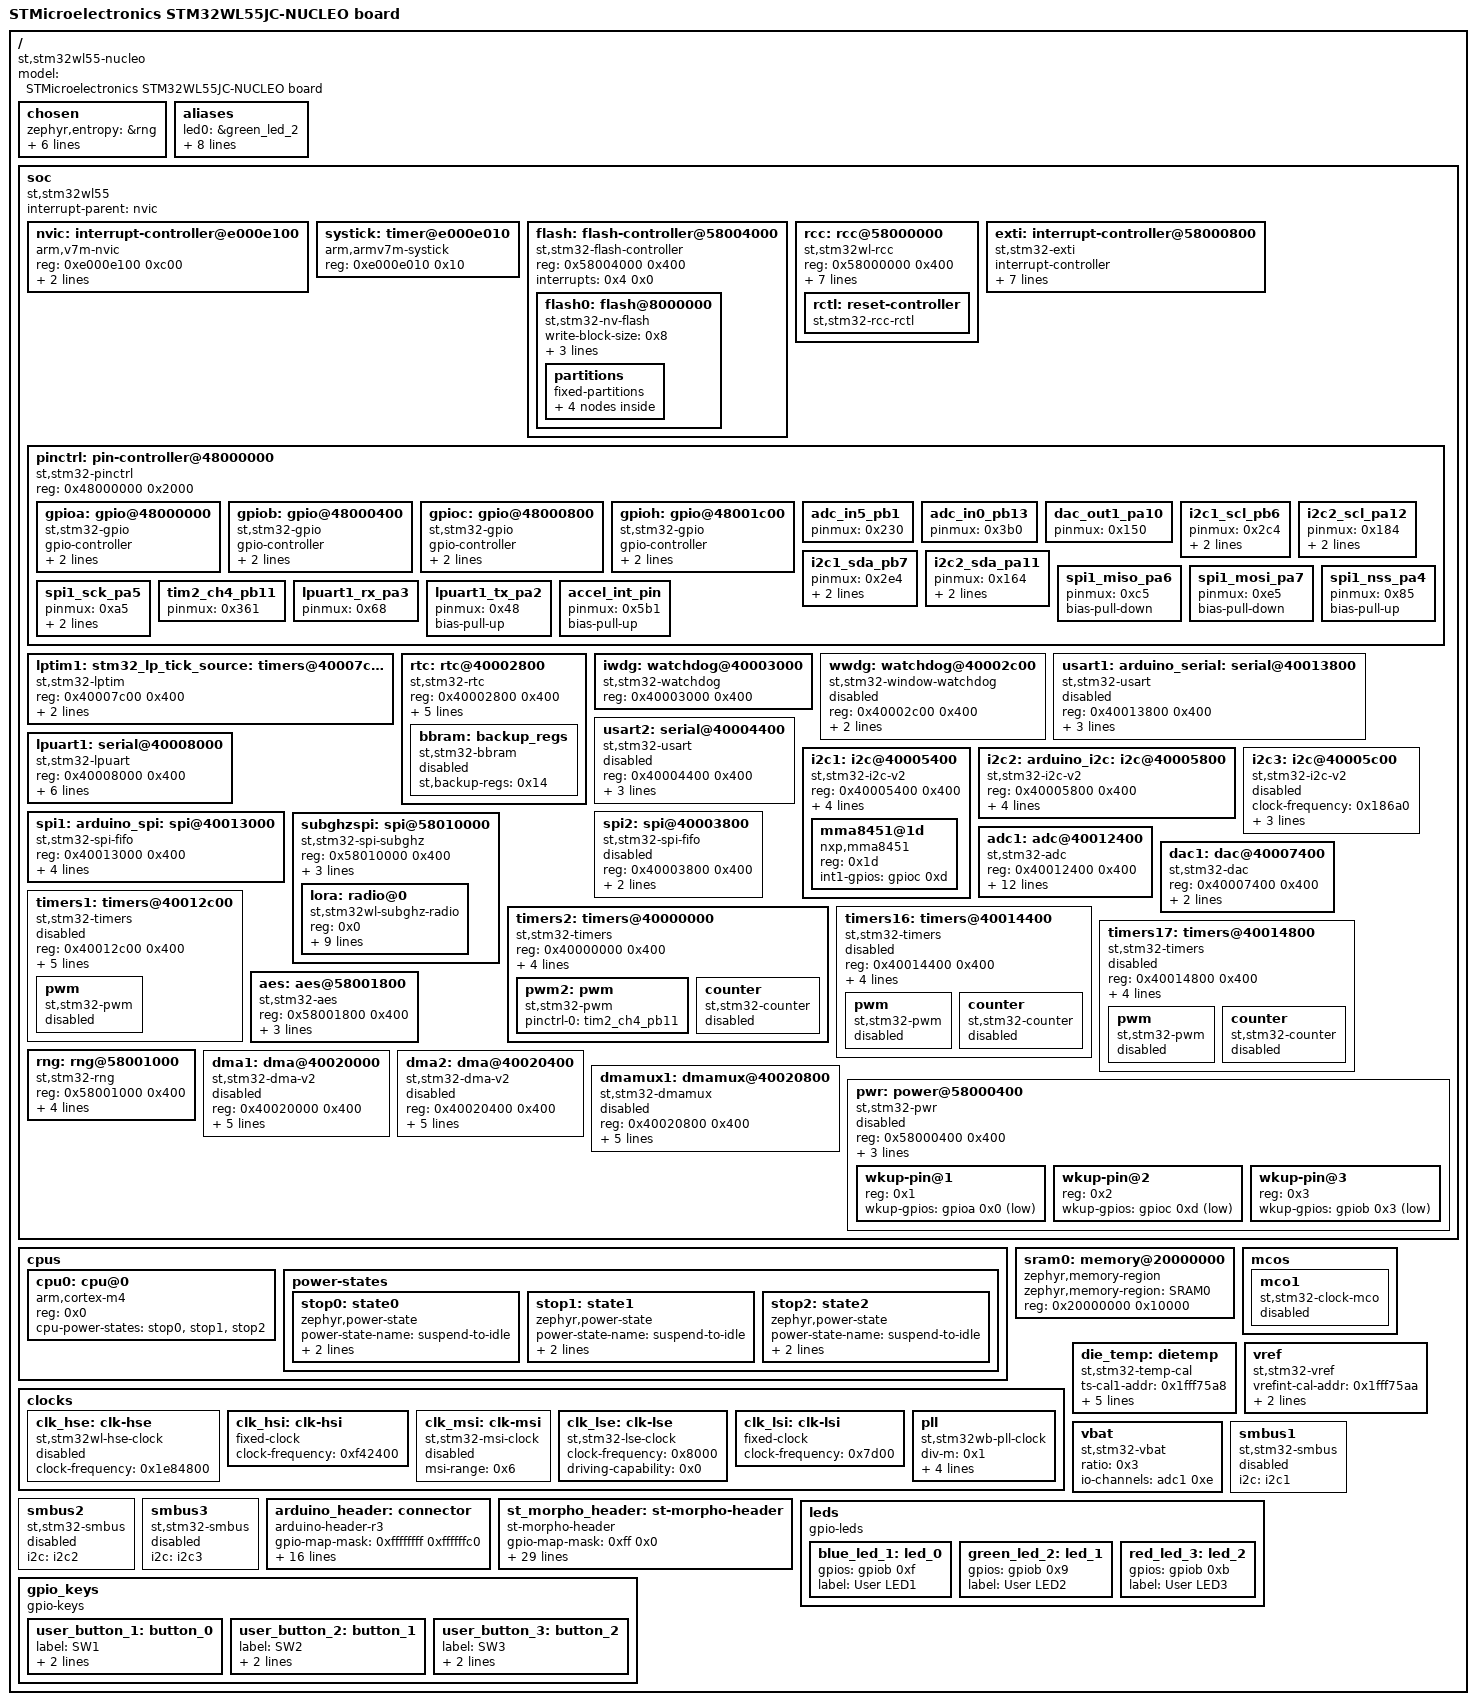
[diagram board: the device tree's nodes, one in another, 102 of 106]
/dts-v1/;

/* node '/' defined in zephyr\dts\common\skeleton.dtsi:9 */
/ {
	#address-cells = < 0x1 >;                              /* in zephyr\dts\common\skeleton.dtsi:10 */
	#size-cells = < 0x1 >;                                 /* in zephyr\dts\common\skeleton.dtsi:11 */
	model = "STMicroelectronics STM32WL55JC-NUCLEO board"; /* in zephyr\boards\st\nucleo_wl55jc\nucleo_wl55jc.dts:15 */
	compatible = "st,stm32wl55-nucleo";                    /* in zephyr\boards\st\nucleo_wl55jc\nucleo_wl55jc.dts:16 */

	/* node '/chosen' defined in zephyr\dts\common\skeleton.dtsi:13 */
	chosen {
		zephyr,entropy = &rng;                    /* in zephyr\dts\arm\st\wl\stm32wl.dtsi:23 */
		zephyr,flash-controller = &flash;         /* in zephyr\dts\arm\st\wl\stm32wl.dtsi:24 */
		zephyr,console = &lpuart1;                /* in zephyr\boards\st\nucleo_wl55jc\nucleo_wl55jc.dts:19 */
		zephyr,shell-uart = &lpuart1;             /* in zephyr\boards\st\nucleo_wl55jc\nucleo_wl55jc.dts:20 */
		zephyr,sram = &sram0;                     /* in zephyr\boards\st\nucleo_wl55jc\nucleo_wl55jc.dts:21 */
		zephyr,flash = &flash0;                   /* in zephyr\boards\st\nucleo_wl55jc\nucleo_wl55jc.dts:22 */
		zephyr,code-partition = &slot0_partition; /* in zephyr\boards\st\nucleo_wl55jc\nucleo_wl55jc.dts:23 */
	};

	/* node '/aliases' defined in zephyr\dts\common\skeleton.dtsi:15 */
	aliases {
		led0 = &green_led_2;   /* in zephyr\boards\st\nucleo_wl55jc\nucleo_wl55jc.dts:68 */
		sw0 = &user_button_1;  /* in zephyr\boards\st\nucleo_wl55jc\nucleo_wl55jc.dts:69 */
		sw1 = &user_button_2;  /* in zephyr\boards\st\nucleo_wl55jc\nucleo_wl55jc.dts:70 */
		sw2 = &user_button_3;  /* in zephyr\boards\st\nucleo_wl55jc\nucleo_wl55jc.dts:71 */
		lora0 = &lora;         /* in zephyr\boards\st\nucleo_wl55jc\nucleo_wl55jc.dts:72 */
		watchdog0 = &iwdg;     /* in zephyr\boards\st\nucleo_wl55jc\nucleo_wl55jc.dts:73 */
		die-temp0 = &die_temp; /* in zephyr\boards\st\nucleo_wl55jc\nucleo_wl55jc.dts:74 */
		volt-sensor0 = &vref;  /* in zephyr\boards\st\nucleo_wl55jc\nucleo_wl55jc.dts:75 */
		volt-sensor1 = &vbat;  /* in zephyr\boards\st\nucleo_wl55jc\nucleo_wl55jc.dts:76 */
	};

	/* node '/soc' defined in zephyr\dts\arm\armv7-m.dtsi:6 */
	soc {
		#address-cells = < 0x1 >;     /* in zephyr\dts\arm\armv7-m.dtsi:7 */
		#size-cells = < 0x1 >;        /* in zephyr\dts\arm\armv7-m.dtsi:8 */
		interrupt-parent = < &nvic >; /* in zephyr\dts\arm\armv7-m.dtsi:10 */
		ranges;                       /* in zephyr\dts\arm\armv7-m.dtsi:11 */
		compatible = "st,stm32wl55",
		             "st,stm32wl",
		             "simple-bus";    /* in zephyr\dts\arm\st\wl\stm32wl55.dtsi:11 */

		/* node '/soc/interrupt-controller@e000e100' defined in zephyr\dts\arm\armv7-m.dtsi:13 */
		nvic: interrupt-controller@e000e100 {
			#address-cells = < 0x1 >;            /* in zephyr\dts\arm\armv7-m.dtsi:14 */
			compatible = "arm,v7m-nvic";         /* in zephyr\dts\arm\armv7-m.dtsi:15 */
			reg = < 0xe000e100 0xc00 >;          /* in zephyr\dts\arm\armv7-m.dtsi:16 */
			interrupt-controller;                /* in zephyr\dts\arm\armv7-m.dtsi:17 */
			#interrupt-cells = < 0x2 >;          /* in zephyr\dts\arm\armv7-m.dtsi:18 */
			arm,num-irq-priority-bits = < 0x4 >; /* in zephyr\dts\arm\st\wl\stm32wl.dtsi:601 */
			phandle = < 0x1 >;                   /* in zephyr\dts\arm\armv7-m.dtsi:10 */
		};

		/* node '/soc/timer@e000e010' defined in zephyr\dts\arm\armv7-m.dtsi:21 */
		systick: timer@e000e010 {
			compatible = "arm,armv7m-systick"; /* in zephyr\dts\arm\armv7-m.dtsi:22 */
			reg = < 0xe000e010 0x10 >;         /* in zephyr\dts\arm\armv7-m.dtsi:23 */
		};

		/* node '/soc/flash-controller@58004000' defined in zephyr\dts\arm\st\wl\stm32wl.dtsi:120 */
		flash: flash-controller@58004000 {
			compatible = "st,stm32-flash-controller",
			             "st,stm32l4-flash-controller"; /* in zephyr\dts\arm\st\wl\stm32wl.dtsi:121 */
			reg = < 0x58004000 0x400 >;                 /* in zephyr\dts\arm\st\wl\stm32wl.dtsi:122 */
			interrupts = < 0x4 0x0 >;                   /* in zephyr\dts\arm\st\wl\stm32wl.dtsi:123 */
			#address-cells = < 0x1 >;                   /* in zephyr\dts\arm\st\wl\stm32wl.dtsi:125 */
			#size-cells = < 0x1 >;                      /* in zephyr\dts\arm\st\wl\stm32wl.dtsi:126 */

			/* node '/soc/flash-controller@58004000/flash@8000000' defined in zephyr\dts\arm\st\wl\stm32wl.dtsi:128 */
			flash0: flash@8000000 {
				compatible = "st,stm32-nv-flash",
				             "soc-nv-flash";      /* in zephyr\dts\arm\st\wl\stm32wl.dtsi:129 */
				write-block-size = < 0x8 >;       /* in zephyr\dts\arm\st\wl\stm32wl.dtsi:131 */
				erase-block-size = < 0x800 >;     /* in zephyr\dts\arm\st\wl\stm32wl.dtsi:132 */
				max-erase-time = < 0x19 >;        /* in zephyr\dts\arm\st\wl\stm32wl.dtsi:134 */
				reg = < 0x8000000 0x40000 >;      /* in zephyr\dts\arm\st\wl\stm32wl55Xc.dtsi:17 */

				/* node '/soc/flash-controller@58004000/flash@8000000/partitions' defined in zephyr\boards\st\nucleo_wl55jc\nucleo_wl55jc.dts:199 */
				partitions {
					compatible = "fixed-partitions"; /* in zephyr\boards\st\nucleo_wl55jc\nucleo_wl55jc.dts:200 */
					#address-cells = < 0x1 >;        /* in zephyr\boards\st\nucleo_wl55jc\nucleo_wl55jc.dts:201 */
					#size-cells = < 0x1 >;           /* in zephyr\boards\st\nucleo_wl55jc\nucleo_wl55jc.dts:202 */

					/* node '/soc/flash-controller@58004000/flash@8000000/partitions/partition@0' defined in zephyr\boards\st\nucleo_wl55jc\nucleo_wl55jc.dts:204 */
					boot_partition: partition@0 {
						label = "mcuboot";    /* in zephyr\boards\st\nucleo_wl55jc\nucleo_wl55jc.dts:205 */
						reg = < 0x0 0x8000 >; /* in zephyr\boards\st\nucleo_wl55jc\nucleo_wl55jc.dts:206 */
						read-only;            /* in zephyr\boards\st\nucleo_wl55jc\nucleo_wl55jc.dts:207 */
					};

					/* node '/soc/flash-controller@58004000/flash@8000000/partitions/partition@8000' defined in zephyr\boards\st\nucleo_wl55jc\nucleo_wl55jc.dts:210 */
					slot0_partition: partition@8000 {
						label = "image-0";        /* in zephyr\boards\st\nucleo_wl55jc\nucleo_wl55jc.dts:211 */
						reg = < 0x8000 0x1a000 >; /* in zephyr\boards\st\nucleo_wl55jc\nucleo_wl55jc.dts:212 */
					};

					/* node '/soc/flash-controller@58004000/flash@8000000/partitions/partition@22000' defined in zephyr\boards\st\nucleo_wl55jc\nucleo_wl55jc.dts:215 */
					slot1_partition: partition@22000 {
						label = "image-1";         /* in zephyr\boards\st\nucleo_wl55jc\nucleo_wl55jc.dts:216 */
						reg = < 0x22000 0x1a000 >; /* in zephyr\boards\st\nucleo_wl55jc\nucleo_wl55jc.dts:217 */
					};

					/* node '/soc/flash-controller@58004000/flash@8000000/partitions/partition@3c000' defined in zephyr\boards\st\nucleo_wl55jc\nucleo_wl55jc.dts:224 */
					storage_partition: partition@3c000 {
						label = "storage";        /* in zephyr\boards\st\nucleo_wl55jc\nucleo_wl55jc.dts:225 */
						reg = < 0x3c000 0x4000 >; /* in zephyr\boards\st\nucleo_wl55jc\nucleo_wl55jc.dts:226 */
					};
				};
			};
		};

		/* node '/soc/rcc@58000000' defined in zephyr\dts\arm\st\wl\stm32wl.dtsi:138 */
		rcc: rcc@58000000 {
			compatible = "st,stm32wl-rcc";   /* in zephyr\dts\arm\st\wl\stm32wl.dtsi:139 */
			#clock-cells = < 0x2 >;          /* in zephyr\dts\arm\st\wl\stm32wl.dtsi:140 */
			reg = < 0x58000000 0x400 >;      /* in zephyr\dts\arm\st\wl\stm32wl.dtsi:141 */
			clocks = < &pll >;               /* in zephyr\boards\st\nucleo_wl55jc\nucleo_wl55jc.dts:108 */
			clock-frequency = < 0x2dc6c00 >; /* in zephyr\boards\st\nucleo_wl55jc\nucleo_wl55jc.dts:109 */
			cpu1-prescaler = < 0x1 >;        /* in zephyr\boards\st\nucleo_wl55jc\nucleo_wl55jc.dts:110 */
			cpu2-prescaler = < 0x1 >;        /* in zephyr\boards\st\nucleo_wl55jc\nucleo_wl55jc.dts:111 */
			ahb3-prescaler = < 0x1 >;        /* in zephyr\boards\st\nucleo_wl55jc\nucleo_wl55jc.dts:112 */
			apb1-prescaler = < 0x1 >;        /* in zephyr\boards\st\nucleo_wl55jc\nucleo_wl55jc.dts:113 */
			apb2-prescaler = < 0x1 >;        /* in zephyr\boards\st\nucleo_wl55jc\nucleo_wl55jc.dts:114 */
			phandle = < 0x3 >;               /* in zephyr\dts\arm\st\wl\stm32wl.dtsi:155 */

			/* node '/soc/rcc@58000000/reset-controller' defined in zephyr\dts\arm\st\wl\stm32wl.dtsi:143 */
			rctl: reset-controller {
				compatible = "st,stm32-rcc-rctl"; /* in zephyr\dts\arm\st\wl\stm32wl.dtsi:144 */
				#reset-cells = < 0x1 >;           /* in zephyr\dts\arm\st\wl\stm32wl.dtsi:145 */
				phandle = < 0x4 >;                /* in zephyr\dts\arm\st\wl\stm32wl.dtsi:256 */
			};
		};

		/* node '/soc/interrupt-controller@58000800' defined in zephyr\dts\arm\st\wl\stm32wl.dtsi:149 */
		exti: interrupt-controller@58000800 {
			compatible = "st,stm32-exti";  /* in zephyr\dts\arm\st\wl\stm32wl.dtsi:150 */
			interrupt-controller;          /* in zephyr\dts\arm\st\wl\stm32wl.dtsi:151 */
			#interrupt-cells = < 0x1 >;    /* in zephyr\dts\arm\st\wl\stm32wl.dtsi:152 */
			#address-cells = < 0x1 >;      /* in zephyr\dts\arm\st\wl\stm32wl.dtsi:153 */
			reg = < 0x58000800 0x400 >;    /* in zephyr\dts\arm\st\wl\stm32wl.dtsi:154 */
			clocks = < &rcc 0x54 0x100 >;  /* in zephyr\dts\arm\st\wl\stm32wl.dtsi:155 */
			num-lines = < 0x40 >;          /* in zephyr\dts\arm\st\wl\stm32wl.dtsi:156 */
			interrupts = < 0x6 0x0 >,
			             < 0x7 0x0 >,
			             < 0x8 0x0 >,
			             < 0x9 0x0 >,
			             < 0xa 0x0 >,
			             < 0x16 0x0 >,
			             < 0x29 0x0 >;     /* in zephyr\dts\arm\st\wl\stm32wl.dtsi:157 */
			interrupt-names = "line0",
			                  "line1",
			                  "line2",
			                  "line3",
			                  "line4",
			                  "line5-9",
			                  "line10-15"; /* in zephyr\dts\arm\st\wl\stm32wl.dtsi:159 */
			line-ranges = < 0x0 0x1 >,
			              < 0x1 0x1 >,
			              < 0x2 0x1 >,
			              < 0x3 0x1 >,
			              < 0x4 0x1 >,
			              < 0x5 0x5 >,
			              < 0xa 0x6 >;     /* in zephyr\dts\arm\st\wl\stm32wl.dtsi:161 */
		};

		/* node '/soc/pin-controller@48000000' defined in zephyr\dts\arm\st\wl\stm32wl.dtsi:165 */
		pinctrl: pin-controller@48000000 {
			compatible = "st,stm32-pinctrl"; /* in zephyr\dts\arm\st\wl\stm32wl.dtsi:166 */
			#address-cells = < 0x1 >;        /* in zephyr\dts\arm\st\wl\stm32wl.dtsi:167 */
			#size-cells = < 0x1 >;           /* in zephyr\dts\arm\st\wl\stm32wl.dtsi:168 */
			reg = < 0x48000000 0x2000 >;     /* in zephyr\dts\arm\st\wl\stm32wl.dtsi:169 */

			/* node '/soc/pin-controller@48000000/gpio@48000000' defined in zephyr\dts\arm\st\wl\stm32wl.dtsi:171 */
			gpioa: gpio@48000000 {
				compatible = "st,stm32-gpio"; /* in zephyr\dts\arm\st\wl\stm32wl.dtsi:172 */
				gpio-controller;              /* in zephyr\dts\arm\st\wl\stm32wl.dtsi:173 */
				#gpio-cells = < 0x2 >;        /* in zephyr\dts\arm\st\wl\stm32wl.dtsi:174 */
				reg = < 0x48000000 0x400 >;   /* in zephyr\dts\arm\st\wl\stm32wl.dtsi:175 */
				clocks = < &rcc 0x4c 0x1 >;   /* in zephyr\dts\arm\st\wl\stm32wl.dtsi:176 */
				phandle = < 0x14 >;           /* in zephyr\dts\arm\st\wl\stm32wl.dtsi:534 */
			};

			/* node '/soc/pin-controller@48000000/gpio@48000400' defined in zephyr\dts\arm\st\wl\stm32wl.dtsi:179 */
			gpiob: gpio@48000400 {
				compatible = "st,stm32-gpio"; /* in zephyr\dts\arm\st\wl\stm32wl.dtsi:180 */
				gpio-controller;              /* in zephyr\dts\arm\st\wl\stm32wl.dtsi:181 */
				#gpio-cells = < 0x2 >;        /* in zephyr\dts\arm\st\wl\stm32wl.dtsi:182 */
				reg = < 0x48000400 0x400 >;   /* in zephyr\dts\arm\st\wl\stm32wl.dtsi:183 */
				clocks = < &rcc 0x4c 0x2 >;   /* in zephyr\dts\arm\st\wl\stm32wl.dtsi:184 */
				phandle = < 0x15 >;           /* in zephyr\dts\arm\st\wl\stm32wl.dtsi:544 */
			};

			/* node '/soc/pin-controller@48000000/gpio@48000800' defined in zephyr\dts\arm\st\wl\stm32wl.dtsi:187 */
			gpioc: gpio@48000800 {
				compatible = "st,stm32-gpio"; /* in zephyr\dts\arm\st\wl\stm32wl.dtsi:188 */
				gpio-controller;              /* in zephyr\dts\arm\st\wl\stm32wl.dtsi:189 */
				#gpio-cells = < 0x2 >;        /* in zephyr\dts\arm\st\wl\stm32wl.dtsi:190 */
				reg = < 0x48000800 0x400 >;   /* in zephyr\dts\arm\st\wl\stm32wl.dtsi:191 */
				clocks = < &rcc 0x4c 0x4 >;   /* in zephyr\dts\arm\st\wl\stm32wl.dtsi:192 */
				phandle = < 0x9 >;            /* in ..\Desktop\Universidad\Master\Embedded\prototipo_acelerometro\build\zephyr\boards\nucleo_wl55jc.overlay:15 */
			};

			/* node '/soc/pin-controller@48000000/gpio@48001c00' defined in zephyr\dts\arm\st\wl\stm32wl.dtsi:195 */
			gpioh: gpio@48001c00 {
				compatible = "st,stm32-gpio"; /* in zephyr\dts\arm\st\wl\stm32wl.dtsi:196 */
				gpio-controller;              /* in zephyr\dts\arm\st\wl\stm32wl.dtsi:197 */
				#gpio-cells = < 0x2 >;        /* in zephyr\dts\arm\st\wl\stm32wl.dtsi:198 */
				reg = < 0x48001c00 0x400 >;   /* in zephyr\dts\arm\st\wl\stm32wl.dtsi:199 */
				clocks = < &rcc 0x4c 0x80 >;  /* in zephyr\dts\arm\st\wl\stm32wl.dtsi:200 */
				phandle = < 0x1e >;           /* in zephyr\boards\st\nucleo_wl55jc\st_morpho_connector.dtsi:15 */
			};

			/* node '/soc/pin-controller@48000000/adc_in5_pb1' defined in modules\hal\stm32\dts\st\wl\stm32wl55jcix-pinctrl.dtsi:39 */
			adc_in5_pb1: adc_in5_pb1 {
				pinmux = < 0x230 >; /* in modules\hal\stm32\dts\st\wl\stm32wl55jcix-pinctrl.dtsi:40 */
				phandle = < 0x10 >; /* in zephyr\boards\st\nucleo_wl55jc\nucleo_wl55jc.dts:155 */
			};

			/* node '/soc/pin-controller@48000000/adc_in0_pb13' defined in modules\hal\stm32\dts\st\wl\stm32wl55jcix-pinctrl.dtsi:55 */
			adc_in0_pb13: adc_in0_pb13 {
				pinmux = < 0x3b0 >; /* in modules\hal\stm32\dts\st\wl\stm32wl55jcix-pinctrl.dtsi:56 */
				phandle = < 0x11 >; /* in zephyr\boards\st\nucleo_wl55jc\nucleo_wl55jc.dts:155 */
			};

			/* node '/soc/pin-controller@48000000/dac_out1_pa10' defined in modules\hal\stm32\dts\st\wl\stm32wl55jcix-pinctrl.dtsi:323 */
			dac_out1_pa10: dac_out1_pa10 {
				pinmux = < 0x150 >; /* in modules\hal\stm32\dts\st\wl\stm32wl55jcix-pinctrl.dtsi:324 */
				phandle = < 0x12 >; /* in zephyr\boards\st\nucleo_wl55jc\nucleo_wl55jc.dts:139 */
			};

			/* node '/soc/pin-controller@48000000/i2c1_scl_pb6' defined in modules\hal\stm32\dts\st\wl\stm32wl55jcix-pinctrl.dtsi:335 */
			i2c1_scl_pb6: i2c1_scl_pb6 {
				pinmux = < 0x2c4 >; /* in modules\hal\stm32\dts\st\wl\stm32wl55jcix-pinctrl.dtsi:336 */
				bias-pull-up;       /* in modules\hal\stm32\dts\st\wl\stm32wl55jcix-pinctrl.dtsi:337 */
				drive-open-drain;   /* in modules\hal\stm32\dts\st\wl\stm32wl55jcix-pinctrl.dtsi:338 */
				phandle = < 0x7 >;  /* in ..\Desktop\Universidad\Master\Embedded\prototipo_acelerometro\build\zephyr\boards\nucleo_wl55jc.overlay:6 */
			};

			/* node '/soc/pin-controller@48000000/i2c2_scl_pa12' defined in modules\hal\stm32\dts\st\wl\stm32wl55jcix-pinctrl.dtsi:347 */
			i2c2_scl_pa12: i2c2_scl_pa12 {
				pinmux = < 0x184 >; /* in modules\hal\stm32\dts\st\wl\stm32wl55jcix-pinctrl.dtsi:348 */
				bias-pull-up;       /* in modules\hal\stm32\dts\st\wl\stm32wl55jcix-pinctrl.dtsi:349 */
				drive-open-drain;   /* in modules\hal\stm32\dts\st\wl\stm32wl55jcix-pinctrl.dtsi:350 */
				phandle = < 0xa >;  /* in zephyr\boards\st\nucleo_wl55jc\nucleo_wl55jc.dts:125 */
			};

			/* node '/soc/pin-controller@48000000/i2c1_sda_pb7' defined in modules\hal\stm32\dts\st\wl\stm32wl55jcix-pinctrl.dtsi:391 */
			i2c1_sda_pb7: i2c1_sda_pb7 {
				pinmux = < 0x2e4 >; /* in modules\hal\stm32\dts\st\wl\stm32wl55jcix-pinctrl.dtsi:392 */
				bias-pull-up;       /* in modules\hal\stm32\dts\st\wl\stm32wl55jcix-pinctrl.dtsi:393 */
				drive-open-drain;   /* in modules\hal\stm32\dts\st\wl\stm32wl55jcix-pinctrl.dtsi:394 */
				phandle = < 0x8 >;  /* in ..\Desktop\Universidad\Master\Embedded\prototipo_acelerometro\build\zephyr\boards\nucleo_wl55jc.overlay:6 */
			};

			/* node '/soc/pin-controller@48000000/i2c2_sda_pa11' defined in modules\hal\stm32\dts\st\wl\stm32wl55jcix-pinctrl.dtsi:403 */
			i2c2_sda_pa11: i2c2_sda_pa11 {
				pinmux = < 0x164 >; /* in modules\hal\stm32\dts\st\wl\stm32wl55jcix-pinctrl.dtsi:404 */
				bias-pull-up;       /* in modules\hal\stm32\dts\st\wl\stm32wl55jcix-pinctrl.dtsi:405 */
				drive-open-drain;   /* in modules\hal\stm32\dts\st\wl\stm32wl55jcix-pinctrl.dtsi:406 */
				phandle = < 0xb >;  /* in zephyr\boards\st\nucleo_wl55jc\nucleo_wl55jc.dts:125 */
			};

			/* node '/soc/pin-controller@48000000/spi1_miso_pa6' defined in modules\hal\stm32\dts\st\wl\stm32wl55jcix-pinctrl.dtsi:583 */
			spi1_miso_pa6: spi1_miso_pa6 {
				pinmux = < 0xc5 >; /* in modules\hal\stm32\dts\st\wl\stm32wl55jcix-pinctrl.dtsi:584 */
				bias-pull-down;    /* in modules\hal\stm32\dts\st\wl\stm32wl55jcix-pinctrl.dtsi:585 */
				phandle = < 0xe >; /* in zephyr\boards\st\nucleo_wl55jc\nucleo_wl55jc.dts:132 */
			};

			/* node '/soc/pin-controller@48000000/spi1_mosi_pa7' defined in modules\hal\stm32\dts\st\wl\stm32wl55jcix-pinctrl.dtsi:615 */
			spi1_mosi_pa7: spi1_mosi_pa7 {
				pinmux = < 0xe5 >; /* in modules\hal\stm32\dts\st\wl\stm32wl55jcix-pinctrl.dtsi:616 */
				bias-pull-down;    /* in modules\hal\stm32\dts\st\wl\stm32wl55jcix-pinctrl.dtsi:617 */
				phandle = < 0xf >; /* in zephyr\boards\st\nucleo_wl55jc\nucleo_wl55jc.dts:132 */
			};

			/* node '/soc/pin-controller@48000000/spi1_nss_pa4' defined in modules\hal\stm32\dts\st\wl\stm32wl55jcix-pinctrl.dtsi:652 */
			spi1_nss_pa4: spi1_nss_pa4 {
				pinmux = < 0x85 >; /* in modules\hal\stm32\dts\st\wl\stm32wl55jcix-pinctrl.dtsi:653 */
				bias-pull-up;      /* in modules\hal\stm32\dts\st\wl\stm32wl55jcix-pinctrl.dtsi:654 */
				phandle = < 0xc >; /* in zephyr\boards\st\nucleo_wl55jc\nucleo_wl55jc.dts:132 */
			};

			/* node '/soc/pin-controller@48000000/spi1_sck_pa5' defined in modules\hal\stm32\dts\st\wl\stm32wl55jcix-pinctrl.dtsi:690 */
			spi1_sck_pa5: spi1_sck_pa5 {
				pinmux = < 0xa5 >;             /* in modules\hal\stm32\dts\st\wl\stm32wl55jcix-pinctrl.dtsi:691 */
				bias-pull-down;                /* in modules\hal\stm32\dts\st\wl\stm32wl55jcix-pinctrl.dtsi:692 */
				slew-rate = "very-high-speed"; /* in modules\hal\stm32\dts\st\wl\stm32wl55jcix-pinctrl.dtsi:693 */
				phandle = < 0xd >;             /* in zephyr\boards\st\nucleo_wl55jc\nucleo_wl55jc.dts:132 */
			};

			/* node '/soc/pin-controller@48000000/tim2_ch4_pb11' defined in modules\hal\stm32\dts\st\wl\stm32wl55jcix-pinctrl.dtsi:830 */
			tim2_ch4_pb11: tim2_ch4_pb11 {
				pinmux = < 0x361 >; /* in modules\hal\stm32\dts\st\wl\stm32wl55jcix-pinctrl.dtsi:831 */
				phandle = < 0x13 >; /* in zephyr\boards\st\nucleo_wl55jc\nucleo_wl55jc.dts:149 */
			};

			/* node '/soc/pin-controller@48000000/lpuart1_rx_pa3' defined in modules\hal\stm32\dts\st\wl\stm32wl55jcix-pinctrl.dtsi:941 */
			lpuart1_rx_pa3: lpuart1_rx_pa3 {
				pinmux = < 0x68 >; /* in modules\hal\stm32\dts\st\wl\stm32wl55jcix-pinctrl.dtsi:942 */
				phandle = < 0x6 >; /* in zephyr\boards\st\nucleo_wl55jc\nucleo_wl55jc.dts:118 */
			};

			/* node '/soc/pin-controller@48000000/lpuart1_tx_pa2' defined in modules\hal\stm32\dts\st\wl\stm32wl55jcix-pinctrl.dtsi:967 */
			lpuart1_tx_pa2: lpuart1_tx_pa2 {
				pinmux = < 0x48 >; /* in modules\hal\stm32\dts\st\wl\stm32wl55jcix-pinctrl.dtsi:968 */
				bias-pull-up;      /* in modules\hal\stm32\dts\st\wl\stm32wl55jcix-pinctrl.dtsi:969 */
				phandle = < 0x5 >; /* in zephyr\boards\st\nucleo_wl55jc\nucleo_wl55jc.dts:118 */
			};

			/* node '/soc/pin-controller@48000000/accel_int_pin' defined in ..\Desktop\Universidad\Master\Embedded\prototipo_acelerometro\build\zephyr\boards\nucleo_wl55jc.overlay:22 */
			accel_int_pin: accel_int_pin {
				pinmux = < 0x5b1 >; /* in ..\Desktop\Universidad\Master\Embedded\prototipo_acelerometro\build\zephyr\boards\nucleo_wl55jc.overlay:23 */
				bias-pull-up;       /* in ..\Desktop\Universidad\Master\Embedded\prototipo_acelerometro\build\zephyr\boards\nucleo_wl55jc.overlay:24 */
			};
		};

		/* node '/soc/timers@40007c00' defined in zephyr\dts\arm\st\wl\stm32wl.dtsi:204 */
		lptim1: stm32_lp_tick_source: timers@40007c00 {
			compatible = "st,stm32-lptim";     /* in zephyr\dts\arm\st\wl\stm32wl.dtsi:205 */
			#address-cells = < 0x1 >;          /* in zephyr\dts\arm\st\wl\stm32wl.dtsi:207 */
			#size-cells = < 0x0 >;             /* in zephyr\dts\arm\st\wl\stm32wl.dtsi:208 */
			reg = < 0x40007c00 0x400 >;        /* in zephyr\dts\arm\st\wl\stm32wl.dtsi:209 */
			interrupts = < 0x27 0x1 >;         /* in zephyr\dts\arm\st\wl\stm32wl.dtsi:210 */
			interrupt-names = "wakeup";        /* in zephyr\dts\arm\st\wl\stm32wl.dtsi:211 */
			clocks = < &rcc 0x58 0x80000000 >,
			         < &rcc 0x3 0x8d20088 >;   /* in zephyr\boards\st\nucleo_wl55jc\nucleo_wl55jc.dts:85 */
			status = "okay";                   /* in zephyr\boards\st\nucleo_wl55jc\nucleo_wl55jc.dts:87 */
		};

		/* node '/soc/rtc@40002800' defined in zephyr\dts\arm\st\wl\stm32wl.dtsi:215 */
		rtc: rtc@40002800 {
			compatible = "st,stm32-rtc";     /* in zephyr\dts\arm\st\wl\stm32wl.dtsi:216 */
			reg = < 0x40002800 0x400 >;      /* in zephyr\dts\arm\st\wl\stm32wl.dtsi:217 */
			interrupts = < 0x2a 0x0 >;       /* in zephyr\dts\arm\st\wl\stm32wl.dtsi:218 */
			prescaler = < 0x8000 >;          /* in zephyr\dts\arm\st\wl\stm32wl.dtsi:220 */
			alarms-count = < 0x2 >;          /* in zephyr\dts\arm\st\wl\stm32wl.dtsi:221 */
			alrm-exti-line = < 0x11 >;       /* in zephyr\dts\arm\st\wl\stm32wl.dtsi:222 */
			clocks = < &rcc 0x58 0x400 >,
			         < &rcc 0x2 0x8c80090 >; /* in zephyr\boards\st\nucleo_wl55jc\nucleo_wl55jc.dts:232 */
			status = "okay";                 /* in zephyr\boards\st\nucleo_wl55jc\nucleo_wl55jc.dts:234 */

			/* node '/soc/rtc@40002800/backup_regs' defined in zephyr\dts\arm\st\wl\stm32wl.dtsi:231 */
			bbram: backup_regs {
				compatible = "st,stm32-bbram"; /* in zephyr\dts\arm\st\wl\stm32wl.dtsi:232 */
				st,backup-regs = < 0x14 >;     /* in zephyr\dts\arm\st\wl\stm32wl.dtsi:233 */
				status = "disabled";           /* in zephyr\dts\arm\st\wl\stm32wl.dtsi:234 */
			};
		};

		/* node '/soc/watchdog@40003000' defined in zephyr\dts\arm\st\wl\stm32wl.dtsi:238 */
		iwdg: watchdog@40003000 {
			compatible = "st,stm32-watchdog"; /* in zephyr\dts\arm\st\wl\stm32wl.dtsi:239 */
			reg = < 0x40003000 0x400 >;       /* in zephyr\dts\arm\st\wl\stm32wl.dtsi:240 */
			status = "okay";                  /* in zephyr\boards\st\nucleo_wl55jc\nucleo_wl55jc.dts:175 */
		};

		/* node '/soc/watchdog@40002c00' defined in zephyr\dts\arm\st\wl\stm32wl.dtsi:244 */
		wwdg: watchdog@40002c00 {
			compatible = "st,stm32-window-watchdog"; /* in zephyr\dts\arm\st\wl\stm32wl.dtsi:245 */
			reg = < 0x40002c00 0x400 >;              /* in zephyr\dts\arm\st\wl\stm32wl.dtsi:246 */
			clocks = < &rcc 0x58 0x800 >;            /* in zephyr\dts\arm\st\wl\stm32wl.dtsi:247 */
			interrupts = < 0x0 0x7 >;                /* in zephyr\dts\arm\st\wl\stm32wl.dtsi:248 */
			status = "disabled";                     /* in zephyr\dts\arm\st\wl\stm32wl.dtsi:249 */
		};

		/* node '/soc/serial@40013800' defined in zephyr\dts\arm\st\wl\stm32wl.dtsi:252 */
		usart1: arduino_serial: serial@40013800 {
			compatible = "st,stm32-usart",
			             "st,stm32-uart";  /* in zephyr\dts\arm\st\wl\stm32wl.dtsi:253 */
			reg = < 0x40013800 0x400 >;    /* in zephyr\dts\arm\st\wl\stm32wl.dtsi:254 */
			clocks = < &rcc 0x60 0x4000 >; /* in zephyr\dts\arm\st\wl\stm32wl.dtsi:255 */
			resets = < &rctl 0x80e >;      /* in zephyr\dts\arm\st\wl\stm32wl.dtsi:256 */
			interrupts = < 0x24 0x0 >;     /* in zephyr\dts\arm\st\wl\stm32wl.dtsi:257 */
			status = "disabled";           /* in zephyr\dts\arm\st\wl\stm32wl.dtsi:258 */
		};

		/* node '/soc/serial@40004400' defined in zephyr\dts\arm\st\wl\stm32wl.dtsi:261 */
		usart2: serial@40004400 {
			compatible = "st,stm32-usart",
			             "st,stm32-uart";   /* in zephyr\dts\arm\st\wl\stm32wl.dtsi:262 */
			reg = < 0x40004400 0x400 >;     /* in zephyr\dts\arm\st\wl\stm32wl.dtsi:263 */
			clocks = < &rcc 0x58 0x20000 >; /* in zephyr\dts\arm\st\wl\stm32wl.dtsi:264 */
			resets = < &rctl 0x711 >;       /* in zephyr\dts\arm\st\wl\stm32wl.dtsi:265 */
			interrupts = < 0x25 0x0 >;      /* in zephyr\dts\arm\st\wl\stm32wl.dtsi:266 */
			status = "disabled";            /* in zephyr\dts\arm\st\wl\stm32wl.dtsi:267 */
		};

		/* node '/soc/serial@40008000' defined in zephyr\dts\arm\st\wl\stm32wl.dtsi:270 */
		lpuart1: serial@40008000 {
			compatible = "st,stm32-lpuart",
			             "st,stm32-uart";                    /* in zephyr\dts\arm\st\wl\stm32wl.dtsi:271 */
			reg = < 0x40008000 0x400 >;                      /* in zephyr\dts\arm\st\wl\stm32wl.dtsi:272 */
			clocks = < &rcc 0x5c 0x1 >;                      /* in zephyr\dts\arm\st\wl\stm32wl.dtsi:273 */
			resets = < &rctl 0x780 >;                        /* in zephyr\dts\arm\st\wl\stm32wl.dtsi:274 */
			interrupts = < 0x26 0x0 >;                       /* in zephyr\dts\arm\st\wl\stm32wl.dtsi:275 */
			wakeup-line = < 0x1c >;                          /* in zephyr\dts\arm\st\wl\stm32wl.dtsi:276 */
			pinctrl-0 = < &lpuart1_tx_pa2 &lpuart1_rx_pa3 >; /* in zephyr\boards\st\nucleo_wl55jc\nucleo_wl55jc.dts:118 */
			pinctrl-names = "default";                       /* in zephyr\boards\st\nucleo_wl55jc\nucleo_wl55jc.dts:119 */
			current-speed = < 0x1c200 >;                     /* in zephyr\boards\st\nucleo_wl55jc\nucleo_wl55jc.dts:120 */
			status = "okay";                                 /* in zephyr\boards\st\nucleo_wl55jc\nucleo_wl55jc.dts:121 */
		};

		/* node '/soc/i2c@40005400' defined in zephyr\dts\arm\st\wl\stm32wl.dtsi:280 */
		i2c1: i2c@40005400 {
			compatible = "st,stm32-i2c-v2";              /* in zephyr\dts\arm\st\wl\stm32wl.dtsi:281 */
			#address-cells = < 0x1 >;                    /* in zephyr\dts\arm\st\wl\stm32wl.dtsi:283 */
			#size-cells = < 0x0 >;                       /* in zephyr\dts\arm\st\wl\stm32wl.dtsi:284 */
			reg = < 0x40005400 0x400 >;                  /* in zephyr\dts\arm\st\wl\stm32wl.dtsi:285 */
			clocks = < &rcc 0x58 0x200000 >;             /* in zephyr\dts\arm\st\wl\stm32wl.dtsi:286 */
			interrupts = < 0x1e 0x0 >,
			             < 0x1f 0x0 >;                   /* in zephyr\dts\arm\st\wl\stm32wl.dtsi:287 */
			interrupt-names = "event",
			                  "error";                   /* in zephyr\dts\arm\st\wl\stm32wl.dtsi:288 */
			status = "okay";                             /* in ..\Desktop\Universidad\Master\Embedded\prototipo_acelerometro\build\zephyr\boards\nucleo_wl55jc.overlay:4 */
			clock-frequency = < 0x61a80 >;               /* in ..\Desktop\Universidad\Master\Embedded\prototipo_acelerometro\build\zephyr\boards\nucleo_wl55jc.overlay:5 */
			pinctrl-0 = < &i2c1_scl_pb6 &i2c1_sda_pb7 >; /* in ..\Desktop\Universidad\Master\Embedded\prototipo_acelerometro\build\zephyr\boards\nucleo_wl55jc.overlay:6 */
			pinctrl-names = "default";                   /* in ..\Desktop\Universidad\Master\Embedded\prototipo_acelerometro\build\zephyr\boards\nucleo_wl55jc.overlay:7 */
			phandle = < 0x1b >;                          /* in zephyr\dts\arm\st\wl\stm32wl.dtsi:579 */

			/* node '/soc/i2c@40005400/mma8451@1d' defined in ..\Desktop\Universidad\Master\Embedded\prototipo_acelerometro\build\zephyr\boards\nucleo_wl55jc.overlay:9 */
			mma8451@1d {
				compatible = "nxp,mma8451";      /* in ..\Desktop\Universidad\Master\Embedded\prototipo_acelerometro\build\zephyr\boards\nucleo_wl55jc.overlay:10 */
				reg = < 0x1d >;                  /* in ..\Desktop\Universidad\Master\Embedded\prototipo_acelerometro\build\zephyr\boards\nucleo_wl55jc.overlay:11 */
				status = "okay";                 /* in ..\Desktop\Universidad\Master\Embedded\prototipo_acelerometro\build\zephyr\boards\nucleo_wl55jc.overlay:12 */
				int1-gpios = < &gpioc 0xd 0x0 >; /* in ..\Desktop\Universidad\Master\Embedded\prototipo_acelerometro\build\zephyr\boards\nucleo_wl55jc.overlay:15 */
			};
		};

		/* node '/soc/i2c@40005800' defined in zephyr\dts\arm\st\wl\stm32wl.dtsi:292 */
		i2c2: arduino_i2c: i2c@40005800 {
			compatible = "st,stm32-i2c-v2";                /* in zephyr\dts\arm\st\wl\stm32wl.dtsi:293 */
			#address-cells = < 0x1 >;                      /* in zephyr\dts\arm\st\wl\stm32wl.dtsi:295 */
			#size-cells = < 0x0 >;                         /* in zephyr\dts\arm\st\wl\stm32wl.dtsi:296 */
			reg = < 0x40005800 0x400 >;                    /* in zephyr\dts\arm\st\wl\stm32wl.dtsi:297 */
			clocks = < &rcc 0x58 0x400000 >;               /* in zephyr\dts\arm\st\wl\stm32wl.dtsi:298 */
			interrupts = < 0x20 0x0 >,
			             < 0x21 0x0 >;                     /* in zephyr\dts\arm\st\wl\stm32wl.dtsi:299 */
			interrupt-names = "event",
			                  "error";                     /* in zephyr\dts\arm\st\wl\stm32wl.dtsi:300 */
			pinctrl-0 = < &i2c2_scl_pa12 &i2c2_sda_pa11 >; /* in zephyr\boards\st\nucleo_wl55jc\nucleo_wl55jc.dts:125 */
			pinctrl-names = "default";                     /* in zephyr\boards\st\nucleo_wl55jc\nucleo_wl55jc.dts:126 */
			status = "okay";                               /* in zephyr\boards\st\nucleo_wl55jc\nucleo_wl55jc.dts:127 */
			clock-frequency = < 0x61a80 >;                 /* in zephyr\boards\st\nucleo_wl55jc\nucleo_wl55jc.dts:128 */
			phandle = < 0x1c >;                            /* in zephyr\dts\arm\st\wl\stm32wl.dtsi:587 */
		};

		/* node '/soc/i2c@40005c00' defined in zephyr\dts\arm\st\wl\stm32wl.dtsi:304 */
		i2c3: i2c@40005c00 {
			compatible = "st,stm32-i2c-v2";  /* in zephyr\dts\arm\st\wl\stm32wl.dtsi:305 */
			clock-frequency = < 0x186a0 >;   /* in zephyr\dts\arm\st\wl\stm32wl.dtsi:306 */
			#address-cells = < 0x1 >;        /* in zephyr\dts\arm\st\wl\stm32wl.dtsi:307 */
			#size-cells = < 0x0 >;           /* in zephyr\dts\arm\st\wl\stm32wl.dtsi:308 */
			reg = < 0x40005c00 0x400 >;      /* in zephyr\dts\arm\st\wl\stm32wl.dtsi:309 */
			clocks = < &rcc 0x58 0x800000 >; /* in zephyr\dts\arm\st\wl\stm32wl.dtsi:310 */
			interrupts = < 0x30 0x0 >,
			             < 0x31 0x0 >;       /* in zephyr\dts\arm\st\wl\stm32wl.dtsi:311 */
			interrupt-names = "event",
			                  "error";       /* in zephyr\dts\arm\st\wl\stm32wl.dtsi:312 */
			status = "disabled";             /* in zephyr\dts\arm\st\wl\stm32wl.dtsi:313 */
			phandle = < 0x1d >;              /* in zephyr\dts\arm\st\wl\stm32wl.dtsi:595 */
		};

		/* node '/soc/spi@40013000' defined in zephyr\dts\arm\st\wl\stm32wl.dtsi:316 */
		spi1: arduino_spi: spi@40013000 {
			compatible = "st,stm32-spi-fifo",
			             "st,stm32-spi";                                               /* in zephyr\dts\arm\st\wl\stm32wl.dtsi:317 */
			#address-cells = < 0x1 >;                                                  /* in zephyr\dts\arm\st\wl\stm32wl.dtsi:318 */
			#size-cells = < 0x0 >;                                                     /* in zephyr\dts\arm\st\wl\stm32wl.dtsi:319 */
			reg = < 0x40013000 0x400 >;                                                /* in zephyr\dts\arm\st\wl\stm32wl.dtsi:320 */
			interrupts = < 0x22 0x5 >;                                                 /* in zephyr\dts\arm\st\wl\stm32wl.dtsi:321 */
			clocks = < &rcc 0x60 0x1000 >;                                             /* in zephyr\dts\arm\st\wl\stm32wl.dtsi:322 */
			pinctrl-0 = < &spi1_nss_pa4 &spi1_sck_pa5 &spi1_miso_pa6 &spi1_mosi_pa7 >; /* in zephyr\boards\st\nucleo_wl55jc\nucleo_wl55jc.dts:132 */
			pinctrl-names = "default";                                                 /* in zephyr\boards\st\nucleo_wl55jc\nucleo_wl55jc.dts:134 */
			status = "okay";                                                           /* in zephyr\boards\st\nucleo_wl55jc\nucleo_wl55jc.dts:135 */
		};

		/* node '/soc/spi@40003800' defined in zephyr\dts\arm\st\wl\stm32wl.dtsi:326 */
		spi2: spi@40003800 {
			compatible = "st,stm32-spi-fifo",
			             "st,stm32-spi";      /* in zephyr\dts\arm\st\wl\stm32wl.dtsi:327 */
			#address-cells = < 0x1 >;         /* in zephyr\dts\arm\st\wl\stm32wl.dtsi:328 */
			#size-cells = < 0x0 >;            /* in zephyr\dts\arm\st\wl\stm32wl.dtsi:329 */
			reg = < 0x40003800 0x400 >;       /* in zephyr\dts\arm\st\wl\stm32wl.dtsi:330 */
			interrupts = < 0x23 0x5 >;        /* in zephyr\dts\arm\st\wl\stm32wl.dtsi:331 */
			clocks = < &rcc 0x58 0x4000 >;    /* in zephyr\dts\arm\st\wl\stm32wl.dtsi:332 */
			status = "disabled";              /* in zephyr\dts\arm\st\wl\stm32wl.dtsi:333 */
		};

		/* node '/soc/spi@58010000' defined in zephyr\dts\arm\st\wl\stm32wl.dtsi:336 */
		subghzspi: spi@58010000 {
			compatible = "st,stm32-spi-subghz",
			             "st,stm32-spi-fifo",
			             "st,stm32-spi";        /* in zephyr\dts\arm\st\wl\stm32wl.dtsi:337 */
			#address-cells = < 0x1 >;           /* in zephyr\dts\arm\st\wl\stm32wl.dtsi:338 */
			#size-cells = < 0x0 >;              /* in zephyr\dts\arm\st\wl\stm32wl.dtsi:339 */
			reg = < 0x58010000 0x400 >;         /* in zephyr\dts\arm\st\wl\stm32wl.dtsi:340 */
			interrupts = < 0x2c 0x5 >;          /* in zephyr\dts\arm\st\wl\stm32wl.dtsi:341 */
			clocks = < &rcc 0x64 0x1 >;         /* in zephyr\dts\arm\st\wl\stm32wl.dtsi:342 */
			use-subghzspi-nss;                  /* in zephyr\dts\arm\st\wl\stm32wl.dtsi:344 */
			status = "okay";                    /* in zephyr\boards\st\nucleo_wl55jc\nucleo_wl55jc.dts:179 */

			/* node '/soc/spi@58010000/radio@0' defined in zephyr\dts\arm\st\wl\stm32wl.dtsi:346 */
			lora: radio@0 {
				compatible = "st,stm32wl-subghz-radio"; /* in zephyr\dts\arm\st\wl\stm32wl.dtsi:347 */
				reg = < 0x0 >;                          /* in zephyr\dts\arm\st\wl\stm32wl.dtsi:348 */
				interrupts = < 0x32 0x0 >;              /* in zephyr\dts\arm\st\wl\stm32wl.dtsi:349 */
				spi-max-frequency = < 0x7a1200 >;       /* in zephyr\dts\arm\st\wl\stm32wl.dtsi:350 */
				status = "okay";                        /* in zephyr\boards\st\nucleo_wl55jc\nucleo_wl55jc.dts:182 */
				tx-enable-gpios = < &gpioc 0x4 0x1 >;   /* in zephyr\boards\st\nucleo_wl55jc\nucleo_wl55jc.dts:183 */
				rx-enable-gpios = < &gpioc 0x5 0x1 >;   /* in zephyr\boards\st\nucleo_wl55jc\nucleo_wl55jc.dts:184 */
				dio3-tcxo-voltage = < 0x1 >;            /* in zephyr\boards\st\nucleo_wl55jc\nucleo_wl55jc.dts:185 */
				tcxo-power-startup-delay-ms = < 0x5 >;  /* in zephyr\boards\st\nucleo_wl55jc\nucleo_wl55jc.dts:186 */
				power-amplifier-output = "rfo-hp";      /* in zephyr\boards\st\nucleo_wl55jc\nucleo_wl55jc.dts:192 */
				rfo-lp-max-power = < 0xf >;             /* in zephyr\boards\st\nucleo_wl55jc\nucleo_wl55jc.dts:193 */
				rfo-hp-max-power = < 0x16 >;            /* in zephyr\boards\st\nucleo_wl55jc\nucleo_wl55jc.dts:194 */
			};
		};

		/* node '/soc/adc@40012400' defined in zephyr\dts\arm\st\wl\stm32wl.dtsi:355 */
		adc1: adc@40012400 {
			compatible = "st,stm32-adc";                              /* in zephyr\dts\arm\st\wl\stm32wl.dtsi:356 */
			reg = < 0x40012400 0x400 >;                               /* in zephyr\dts\arm\st\wl\stm32wl.dtsi:357 */
			clocks = < &rcc 0x60 0x200 >;                             /* in zephyr\dts\arm\st\wl\stm32wl.dtsi:358 */
			interrupts = < 0x12 0x0 >;                                /* in zephyr\dts\arm\st\wl\stm32wl.dtsi:359 */
			#io-channel-cells = < 0x1 >;                              /* in zephyr\dts\arm\st\wl\stm32wl.dtsi:361 */
			resolutions = < 0x60630c 0x51630c 0x42630c 0x33630c >;    /* in zephyr\dts\arm\st\wl\stm32wl.dtsi:362 */
			sampling-times = < 0x2 0x4 0x8 0xd 0x14 0x28 0x50 0xa1 >; /* in zephyr\dts\arm\st\wl\stm32wl.dtsi:366 */
			num-sampling-time-common-channels = < 0x2 >;              /* in zephyr\dts\arm\st\wl\stm32wl.dtsi:367 */
			st,adc-sequencer = "NOT_FULLY_CONFIGURABLE";              /* in zephyr\dts\arm\st\wl\stm32wl.dtsi:368 */
			st,adc-oversampler = "OVERSAMPLER_MINIMAL";               /* in zephyr\dts\arm\st\wl\stm32wl.dtsi:369 */
			pinctrl-0 = < &adc_in5_pb1 &adc_in0_pb13 >;               /* in zephyr\boards\st\nucleo_wl55jc\nucleo_wl55jc.dts:155 */
			pinctrl-names = "default";                                /* in zephyr\boards\st\nucleo_wl55jc\nucleo_wl55jc.dts:156 */
			st,adc-clock-source = "SYNC";                             /* in zephyr\boards\st\nucleo_wl55jc\nucleo_wl55jc.dts:157 */
			st,adc-prescaler = < 0x4 >;                               /* in zephyr\boards\st\nucleo_wl55jc\nucleo_wl55jc.dts:158 */
			status = "okay";                                          /* in zephyr\boards\st\nucleo_wl55jc\nucleo_wl55jc.dts:159 */
			phandle = < 0x1a >;                                       /* in zephyr\dts\arm\st\wl\stm32wl.dtsi:556 */
		};

		/* node '/soc/dac@40007400' defined in zephyr\dts\arm\st\wl\stm32wl.dtsi:372 */
		dac1: dac@40007400 {
			compatible = "st,stm32-dac";       /* in zephyr\dts\arm\st\wl\stm32wl.dtsi:373 */
			reg = < 0x40007400 0x400 >;        /* in zephyr\dts\arm\st\wl\stm32wl.dtsi:374 */
			clocks = < &rcc 0x58 0x20000000 >; /* in zephyr\dts\arm\st\wl\stm32wl.dtsi:375 */
			#io-channel-cells = < 0x1 >;       /* in zephyr\dts\arm\st\wl\stm32wl.dtsi:377 */
			pinctrl-0 = < &dac_out1_pa10 >;    /* in zephyr\boards\st\nucleo_wl55jc\nucleo_wl55jc.dts:139 */
			pinctrl-names = "default";         /* in zephyr\boards\st\nucleo_wl55jc\nucleo_wl55jc.dts:140 */
			status = "okay";                   /* in zephyr\boards\st\nucleo_wl55jc\nucleo_wl55jc.dts:141 */
		};

		/* node '/soc/timers@40012c00' defined in zephyr\dts\arm\st\wl\stm32wl.dtsi:380 */
		timers1: timers@40012c00 {
			compatible = "st,stm32-timers"; /* in zephyr\dts\arm\st\wl\stm32wl.dtsi:381 */
			reg = < 0x40012c00 0x400 >;     /* in zephyr\dts\arm\st\wl\stm32wl.dtsi:382 */
			clocks = < &rcc 0x60 0x800 >,
			         < &rcc 0x8 0xff >;     /* in zephyr\dts\arm\st\wl\stm32wl.dtsi:383 */
			resets = < &rctl 0x80b >;       /* in zephyr\dts\arm\st\wl\stm32wl.dtsi:385 */
			interrupts = < 0x17 0x0 >,
			             < 0x18 0x0 >,
			             < 0x19 0x0 >,
			             < 0x1a 0x0 >;      /* in zephyr\dts\arm\st\wl\stm32wl.dtsi:386 */
			interrupt-names = "brk",
			                  "up",
			                  "trgcom",
			                  "cc";         /* in zephyr\dts\arm\st\wl\stm32wl.dtsi:387 */
			st,prescaler = < 0x0 >;         /* in zephyr\dts\arm\st\wl\stm32wl.dtsi:388 */
			status = "disabled";            /* in zephyr\dts\arm\st\wl\stm32wl.dtsi:389 */

			/* node '/soc/timers@40012c00/pwm' defined in zephyr\dts\arm\st\wl\stm32wl.dtsi:391 */
			pwm {
				compatible = "st,stm32-pwm"; /* in zephyr\dts\arm\st\wl\stm32wl.dtsi:392 */
				status = "disabled";         /* in zephyr\dts\arm\st\wl\stm32wl.dtsi:393 */
				#pwm-cells = < 0x3 >;        /* in zephyr\dts\arm\st\wl\stm32wl.dtsi:394 */
			};
		};

		/* node '/soc/timers@40000000' defined in zephyr\dts\arm\st\wl\stm32wl.dtsi:398 */
		timers2: timers@40000000 {
			compatible = "st,stm32-timers"; /* in zephyr\dts\arm\st\wl\stm32wl.dtsi:399 */
			reg = < 0x40000000 0x400 >;     /* in zephyr\dts\arm\st\wl\stm32wl.dtsi:400 */
			clocks = < &rcc 0x58 0x1 >,
			         < &rcc 0x7 0xff >;     /* in zephyr\dts\arm\st\wl\stm32wl.dtsi:401 */
			resets = < &rctl 0x700 >;       /* in zephyr\dts\arm\st\wl\stm32wl.dtsi:403 */
			interrupts = < 0x1b 0x0 >;      /* in zephyr\dts\arm\st\wl\stm32wl.dtsi:404 */
			interrupt-names = "global";     /* in zephyr\dts\arm\st\wl\stm32wl.dtsi:405 */
			st,prescaler = < 0x0 >;         /* in zephyr\dts\arm\st\wl\stm32wl.dtsi:406 */
			status = "okay";                /* in zephyr\boards\st\nucleo_wl55jc\nucleo_wl55jc.dts:145 */

			/* node '/soc/timers@40000000/pwm' defined in zephyr\dts\arm\st\wl\stm32wl.dtsi:409 */
			pwm2: pwm {
				compatible = "st,stm32-pwm";    /* in zephyr\dts\arm\st\wl\stm32wl.dtsi:410 */
				#pwm-cells = < 0x3 >;           /* in zephyr\dts\arm\st\wl\stm32wl.dtsi:412 */
				status = "okay";                /* in zephyr\boards\st\nucleo_wl55jc\nucleo_wl55jc.dts:148 */
				pinctrl-0 = < &tim2_ch4_pb11 >; /* in zephyr\boards\st\nucleo_wl55jc\nucleo_wl55jc.dts:149 */
				pinctrl-names = "default";      /* in zephyr\boards\st\nucleo_wl55jc\nucleo_wl55jc.dts:150 */
			};

			/* node '/soc/timers@40000000/counter' defined in zephyr\dts\arm\st\wl\stm32wl.dtsi:415 */
			counter {
				compatible = "st,stm32-counter"; /* in zephyr\dts\arm\st\wl\stm32wl.dtsi:416 */
				status = "disabled";             /* in zephyr\dts\arm\st\wl\stm32wl.dtsi:417 */
			};
		};

		/* node '/soc/timers@40014400' defined in zephyr\dts\arm\st\wl\stm32wl.dtsi:421 */
		timers16: timers@40014400 {
			compatible = "st,stm32-timers"; /* in zephyr\dts\arm\st\wl\stm32wl.dtsi:422 */
			reg = < 0x40014400 0x400 >;     /* in zephyr\dts\arm\st\wl\stm32wl.dtsi:423 */
			clocks = < &rcc 0x60 0x20000 >,
			         < &rcc 0x8 0xff >;     /* in zephyr\dts\arm\st\wl\stm32wl.dtsi:424 */
			resets = < &rctl 0x811 >;       /* in zephyr\dts\arm\st\wl\stm32wl.dtsi:426 */
			interrupts = < 0x1c 0x0 >;      /* in zephyr\dts\arm\st\wl\stm32wl.dtsi:427 */
			interrupt-names = "global";     /* in zephyr\dts\arm\st\wl\stm32wl.dtsi:428 */
			st,prescaler = < 0x0 >;         /* in zephyr\dts\arm\st\wl\stm32wl.dtsi:429 */
			status = "disabled";            /* in zephyr\dts\arm\st\wl\stm32wl.dtsi:430 */

			/* node '/soc/timers@40014400/pwm' defined in zephyr\dts\arm\st\wl\stm32wl.dtsi:432 */
			pwm {
				compatible = "st,stm32-pwm"; /* in zephyr\dts\arm\st\wl\stm32wl.dtsi:433 */
				status = "disabled";         /* in zephyr\dts\arm\st\wl\stm32wl.dtsi:434 */
				#pwm-cells = < 0x3 >;        /* in zephyr\dts\arm\st\wl\stm32wl.dtsi:435 */
			};

			/* node '/soc/timers@40014400/counter' defined in zephyr\dts\arm\st\wl\stm32wl.dtsi:438 */
			counter {
				compatible = "st,stm32-counter"; /* in zephyr\dts\arm\st\wl\stm32wl.dtsi:439 */
				status = "disabled";             /* in zephyr\dts\arm\st\wl\stm32wl.dtsi:440 */
			};
		};

		/* node '/soc/timers@40014800' defined in zephyr\dts\arm\st\wl\stm32wl.dtsi:444 */
		timers17: timers@40014800 {
			compatible = "st,stm32-timers"; /* in zephyr\dts\arm\st\wl\stm32wl.dtsi:445 */
			reg = < 0x40014800 0x400 >;     /* in zephyr\dts\arm\st\wl\stm32wl.dtsi:446 */
			clocks = < &rcc 0x60 0x40000 >,
			         < &rcc 0x8 0xff >;     /* in zephyr\dts\arm\st\wl\stm32wl.dtsi:447 */
			resets = < &rctl 0x812 >;       /* in zephyr\dts\arm\st\wl\stm32wl.dtsi:449 */
			interrupts = < 0x1d 0x0 >;      /* in zephyr\dts\arm\st\wl\stm32wl.dtsi:450 */
			interrupt-names = "global";     /* in zephyr\dts\arm\st\wl\stm32wl.dtsi:451 */
			st,prescaler = < 0x0 >;         /* in zephyr\dts\arm\st\wl\stm32wl.dtsi:452 */
			status = "disabled";            /* in zephyr\dts\arm\st\wl\stm32wl.dtsi:453 */

			/* node '/soc/timers@40014800/pwm' defined in zephyr\dts\arm\st\wl\stm32wl.dtsi:455 */
			pwm {
				compatible = "st,stm32-pwm"; /* in zephyr\dts\arm\st\wl\stm32wl.dtsi:456 */
				status = "disabled";         /* in zephyr\dts\arm\st\wl\stm32wl.dtsi:457 */
				#pwm-cells = < 0x3 >;        /* in zephyr\dts\arm\st\wl\stm32wl.dtsi:458 */
			};

			/* node '/soc/timers@40014800/counter' defined in zephyr\dts\arm\st\wl\stm32wl.dtsi:461 */
			counter {
				compatible = "st,stm32-counter"; /* in zephyr\dts\arm\st\wl\stm32wl.dtsi:462 */
				status = "disabled";             /* in zephyr\dts\arm\st\wl\stm32wl.dtsi:463 */
			};
		};

		/* node '/soc/aes@58001800' defined in zephyr\dts\arm\st\wl\stm32wl.dtsi:467 */
		aes: aes@58001800 {
			compatible = "st,stm32-aes";    /* in zephyr\dts\arm\st\wl\stm32wl.dtsi:468 */
			reg = < 0x58001800 0x400 >;     /* in zephyr\dts\arm\st\wl\stm32wl.dtsi:469 */
			clocks = < &rcc 0x50 0x20000 >; /* in zephyr\dts\arm\st\wl\stm32wl.dtsi:470 */
			resets = < &rctl 0x610 >;       /* in zephyr\dts\arm\st\wl\stm32wl.dtsi:471 */
			interrupts = < 0x33 0x0 >;      /* in zephyr\dts\arm\st\wl\stm32wl.dtsi:472 */
			status = "okay";                /* in zephyr\boards\st\nucleo_wl55jc\nucleo_wl55jc.dts:167 */
		};

		/* node '/soc/rng@58001000' defined in zephyr\dts\arm\st\wl\stm32wl.dtsi:476 */
		rng: rng@58001000 {
			compatible = "st,stm32-rng";        /* in zephyr\dts\arm\st\wl\stm32wl.dtsi:477 */
			reg = < 0x58001000 0x400 >;         /* in zephyr\dts\arm\st\wl\stm32wl.dtsi:478 */
			interrupts = < 0x34 0x0 >;          /* in zephyr\dts\arm\st\wl\stm32wl.dtsi:479 */
			clocks = < &rcc 0x50 0x40000 >;     /* in zephyr\dts\arm\st\wl\stm32wl.dtsi:480 */
			health-test-magic = < 0x17590abc >; /* in zephyr\dts\arm\st\wl\stm32wl.dtsi:481 */
			health-test-config = < 0xaa74 >;    /* in zephyr\dts\arm\st\wl\stm32wl.dtsi:482 */
			status = "okay";                    /* in zephyr\boards\st\nucleo_wl55jc\nucleo_wl55jc.dts:171 */
		};

		/* node '/soc/dma@40020000' defined in zephyr\dts\arm\st\wl\stm32wl.dtsi:486 */
		dma1: dma@40020000 {
			compatible = "st,stm32-dma-v2";                                             /* in zephyr\dts\arm\st\wl\stm32wl.dtsi:487 */
			#dma-cells = < 0x3 >;                                                       /* in zephyr\dts\arm\st\wl\stm32wl.dtsi:488 */
			reg = < 0x40020000 0x400 >;                                                 /* in zephyr\dts\arm\st\wl\stm32wl.dtsi:489 */
			interrupts = < 0xb 0x0 0xc 0x0 0xd 0x0 0xe 0x0 0xf 0x0 0x10 0x0 0x11 0x0 >; /* in zephyr\dts\arm\st\wl\stm32wl.dtsi:490 */
			clocks = < &rcc 0x48 0x1 >;                                                 /* in zephyr\dts\arm\st\wl\stm32wl.dtsi:491 */
			dma-requests = < 0x7 >;                                                     /* in zephyr\dts\arm\st\wl\stm32wl.dtsi:492 */
			dma-offset = < 0x0 >;                                                       /* in zephyr\dts\arm\st\wl\stm32wl.dtsi:493 */
			status = "disabled";                                                        /* in zephyr\dts\arm\st\wl\stm32wl.dtsi:494 */
		};

		/* node '/soc/dma@40020400' defined in zephyr\dts\arm\st\wl\stm32wl.dtsi:497 */
		dma2: dma@40020400 {
			compatible = "st,stm32-dma-v2";                                                  /* in zephyr\dts\arm\st\wl\stm32wl.dtsi:498 */
			#dma-cells = < 0x3 >;                                                            /* in zephyr\dts\arm\st\wl\stm32wl.dtsi:499 */
			reg = < 0x40020400 0x400 >;                                                      /* in zephyr\dts\arm\st\wl\stm32wl.dtsi:500 */
			interrupts = < 0x36 0x0 0x37 0x0 0x38 0x0 0x39 0x0 0x3a 0x0 0x3b 0x0 0x3c 0x0 >; /* in zephyr\dts\arm\st\wl\stm32wl.dtsi:501 */
			clocks = < &rcc 0x48 0x2 >;                                                      /* in zephyr\dts\arm\st\wl\stm32wl.dtsi:502 */
			dma-requests = < 0x7 >;                                                          /* in zephyr\dts\arm\st\wl\stm32wl.dtsi:503 */
			dma-offset = < 0x7 >;                                                            /* in zephyr\dts\arm\st\wl\stm32wl.dtsi:504 */
			status = "disabled";                                                             /* in zephyr\dts\arm\st\wl\stm32wl.dtsi:505 */
		};

		/* node '/soc/dmamux@40020800' defined in zephyr\dts\arm\st\wl\stm32wl.dtsi:508 */
		dmamux1: dmamux@40020800 {
			compatible = "st,stm32-dmamux"; /* in zephyr\dts\arm\st\wl\stm32wl.dtsi:509 */
			#dma-cells = < 0x3 >;           /* in zephyr\dts\arm\st\wl\stm32wl.dtsi:510 */
			reg = < 0x40020800 0x400 >;     /* in zephyr\dts\arm\st\wl\stm32wl.dtsi:511 */
			interrupts = < 0x3d 0x0 >;      /* in zephyr\dts\arm\st\wl\stm32wl.dtsi:512 */
			clocks = < &rcc 0x48 0x4 >;     /* in zephyr\dts\arm\st\wl\stm32wl.dtsi:513 */
			dma-channels = < 0xe >;         /* in zephyr\dts\arm\st\wl\stm32wl.dtsi:514 */
			dma-generators = < 0x4 >;       /* in zephyr\dts\arm\st\wl\stm32wl.dtsi:515 */
			dma-requests = < 0x26 >;        /* in zephyr\dts\arm\st\wl\stm32wl.dtsi:516 */
			status = "disabled";            /* in zephyr\dts\arm\st\wl\stm32wl.dtsi:517 */
		};

		/* node '/soc/power@58000400' defined in zephyr\dts\arm\st\wl\stm32wl.dtsi:520 */
		pwr: power@58000400 {
			compatible = "st,stm32-pwr"; /* in zephyr\dts\arm\st\wl\stm32wl.dtsi:521 */
			reg = < 0x58000400 0x400 >;  /* in zephyr\dts\arm\st\wl\stm32wl.dtsi:522 */
			status = "disabled";         /* in zephyr\dts\arm\st\wl\stm32wl.dtsi:523 */
			wkup-pins-nb = < 0x3 >;      /* in zephyr\dts\arm\st\wl\stm32wl.dtsi:525 */
			wkup-pins-pol;               /* in zephyr\dts\arm\st\wl\stm32wl.dtsi:526 */
			wkup-pins-pupd;              /* in zephyr\dts\arm\st\wl\stm32wl.dtsi:527 */
			#address-cells = < 0x1 >;    /* in zephyr\dts\arm\st\wl\stm32wl.dtsi:529 */
			#size-cells = < 0x0 >;       /* in zephyr\dts\arm\st\wl\stm32wl.dtsi:530 */

			/* node '/soc/power@58000400/wkup-pin@1' defined in zephyr\dts\arm\st\wl\stm32wl.dtsi:532 */
			wkup-pin@1 {
				reg = < 0x1 >;                   /* in zephyr\dts\arm\st\wl\stm32wl.dtsi:533 */
				wkup-gpios = < &gpioa 0x0 0x1 >; /* in zephyr\dts\arm\st\wl\stm32wl.dtsi:534 */
			};

			/* node '/soc/power@58000400/wkup-pin@2' defined in zephyr\dts\arm\st\wl\stm32wl.dtsi:537 */
			wkup-pin@2 {
				reg = < 0x2 >;                   /* in zephyr\dts\arm\st\wl\stm32wl.dtsi:538 */
				wkup-gpios = < &gpioc 0xd 0x1 >; /* in zephyr\dts\arm\st\wl\stm32wl.dtsi:539 */
			};

			/* node '/soc/power@58000400/wkup-pin@3' defined in zephyr\dts\arm\st\wl\stm32wl.dtsi:542 */
			wkup-pin@3 {
				reg = < 0x3 >;                   /* in zephyr\dts\arm\st\wl\stm32wl.dtsi:543 */
				wkup-gpios = < &gpiob 0x3 0x1 >; /* in zephyr\dts\arm\st\wl\stm32wl.dtsi:544 */
			};
		};
	};

	/* node '/cpus' defined in zephyr\dts\arm\st\wl\stm32wl.dtsi:27 */
	cpus {
		#address-cells = < 0x1 >; /* in zephyr\dts\arm\st\wl\stm32wl.dtsi:28 */
		#size-cells = < 0x0 >;    /* in zephyr\dts\arm\st\wl\stm32wl.dtsi:29 */

		/* node '/cpus/cpu@0' defined in zephyr\dts\arm\st\wl\stm32wl.dtsi:31 */
		cpu0: cpu@0 {
			device_type = "cpu";                         /* in zephyr\dts\arm\st\wl\stm32wl.dtsi:32 */
			compatible = "arm,cortex-m4";                /* in zephyr\dts\arm\st\wl\stm32wl.dtsi:33 */
			reg = < 0x0 >;                               /* in zephyr\dts\arm\st\wl\stm32wl.dtsi:34 */
			cpu-power-states = < &stop0 &stop1 &stop2 >; /* in zephyr\dts\arm\st\wl\stm32wl.dtsi:35 */
		};

		/* node '/cpus/power-states' defined in zephyr\dts\arm\st\wl\stm32wl.dtsi:38 */
		power-states {

			/* node '/cpus/power-states/state0' defined in zephyr\dts\arm\st\wl\stm32wl.dtsi:39 */
			stop0: state0 {
				compatible = "zephyr,power-state";    /* in zephyr\dts\arm\st\wl\stm32wl.dtsi:40 */
				power-state-name = "suspend-to-idle"; /* in zephyr\dts\arm\st\wl\stm32wl.dtsi:41 */
				substate-id = < 0x1 >;                /* in zephyr\dts\arm\st\wl\stm32wl.dtsi:42 */
				min-residency-us = < 0x64 >;          /* in zephyr\dts\arm\st\wl\stm32wl.dtsi:43 */
				phandle = < 0x16 >;                   /* in zephyr\dts\arm\st\wl\stm32wl.dtsi:35 */
			};

			/* node '/cpus/power-states/state1' defined in zephyr\dts\arm\st\wl\stm32wl.dtsi:46 */
			stop1: state1 {
				compatible = "zephyr,power-state";    /* in zephyr\dts\arm\st\wl\stm32wl.dtsi:47 */
				power-state-name = "suspend-to-idle"; /* in zephyr\dts\arm\st\wl\stm32wl.dtsi:48 */
				substate-id = < 0x2 >;                /* in zephyr\dts\arm\st\wl\stm32wl.dtsi:49 */
				min-residency-us = < 0x1f4 >;         /* in zephyr\dts\arm\st\wl\stm32wl.dtsi:50 */
				phandle = < 0x17 >;                   /* in zephyr\dts\arm\st\wl\stm32wl.dtsi:35 */
			};

			/* node '/cpus/power-states/state2' defined in zephyr\dts\arm\st\wl\stm32wl.dtsi:53 */
			stop2: state2 {
				compatible = "zephyr,power-state";    /* in zephyr\dts\arm\st\wl\stm32wl.dtsi:54 */
				power-state-name = "suspend-to-idle"; /* in zephyr\dts\arm\st\wl\stm32wl.dtsi:55 */
				substate-id = < 0x3 >;                /* in zephyr\dts\arm\st\wl\stm32wl.dtsi:56 */
				min-residency-us = < 0x384 >;         /* in zephyr\dts\arm\st\wl\stm32wl.dtsi:57 */
				phandle = < 0x18 >;                   /* in zephyr\dts\arm\st\wl\stm32wl.dtsi:35 */
			};
		};
	};

	/* node '/memory@20000000' defined in zephyr\dts\arm\st\wl\stm32wl.dtsi:62 */
	sram0: memory@20000000 {
		compatible = "zephyr,memory-region",
		             "mmio-sram";            /* in zephyr\dts\arm\st\wl\stm32wl.dtsi:63 */
		zephyr,memory-region = "SRAM0";      /* in zephyr\dts\arm\st\wl\stm32wl.dtsi:64 */
		reg = < 0x20000000 0x10000 >;        /* in zephyr\dts\arm\st\wl\stm32wl55Xc.dtsi:11 */
	};

	/* node '/clocks' defined in zephyr\dts\arm\st\wl\stm32wl.dtsi:67 */
	clocks {

		/* node '/clocks/clk-hse' defined in zephyr\dts\arm\st\wl\stm32wl.dtsi:68 */
		clk_hse: clk-hse {
			#clock-cells = < 0x0 >;              /* in zephyr\dts\arm\st\wl\stm32wl.dtsi:69 */
			compatible = "st,stm32wl-hse-clock"; /* in zephyr\dts\arm\st\wl\stm32wl.dtsi:70 */
			clock-frequency = < 0x1e84800 >;     /* in zephyr\dts\arm\st\wl\stm32wl.dtsi:72 */
			status = "disabled";                 /* in zephyr\dts\arm\st\wl\stm32wl.dtsi:73 */
		};

		/* node '/clocks/clk-hsi' defined in zephyr\dts\arm\st\wl\stm32wl.dtsi:76 */
		clk_hsi: clk-hsi {
			#clock-cells = < 0x0 >;         /* in zephyr\dts\arm\st\wl\stm32wl.dtsi:77 */
			compatible = "fixed-clock";     /* in zephyr\dts\arm\st\wl\stm32wl.dtsi:78 */
			clock-frequency = < 0xf42400 >; /* in zephyr\dts\arm\st\wl\stm32wl.dtsi:79 */
			status = "okay";                /* in zephyr\boards\st\nucleo_wl55jc\nucleo_wl55jc.dts:91 */
			phandle = < 0x19 >;             /* in zephyr\boards\st\nucleo_wl55jc\nucleo_wl55jc.dts:103 */
		};

		/* node '/clocks/clk-msi' defined in zephyr\dts\arm\st\wl\stm32wl.dtsi:83 */
		clk_msi: clk-msi {
			#clock-cells = < 0x0 >;            /* in zephyr\dts\arm\st\wl\stm32wl.dtsi:84 */
			compatible = "st,stm32-msi-clock"; /* in zephyr\dts\arm\st\wl\stm32wl.dtsi:85 */
			msi-range = < 0x6 >;               /* in zephyr\dts\arm\st\wl\stm32wl.dtsi:86 */
			status = "disabled";               /* in zephyr\dts\arm\st\wl\stm32wl.dtsi:87 */
		};

		/* node '/clocks/clk-lse' defined in zephyr\dts\arm\st\wl\stm32wl.dtsi:90 */
		clk_lse: clk-lse {
			#clock-cells = < 0x0 >;            /* in zephyr\dts\arm\st\wl\stm32wl.dtsi:91 */
			compatible = "st,stm32-lse-clock"; /* in zephyr\dts\arm\st\wl\stm32wl.dtsi:92 */
			clock-frequency = < 0x8000 >;      /* in zephyr\dts\arm\st\wl\stm32wl.dtsi:93 */
			driving-capability = < 0x0 >;      /* in zephyr\dts\arm\st\wl\stm32wl.dtsi:94 */
			status = "okay";                   /* in zephyr\boards\st\nucleo_wl55jc\nucleo_wl55jc.dts:95 */
		};

		/* node '/clocks/clk-lsi' defined in zephyr\dts\arm\st\wl\stm32wl.dtsi:98 */
		clk_lsi: clk-lsi {
			#clock-cells = < 0x0 >;       /* in zephyr\dts\arm\st\wl\stm32wl.dtsi:99 */
			compatible = "fixed-clock";   /* in zephyr\dts\arm\st\wl\stm32wl.dtsi:100 */
			clock-frequency = < 0x7d00 >; /* in zephyr\dts\arm\st\wl\stm32wl.dtsi:101 */
			status = "okay";              /* in zephyr\boards\st\nucleo_wl55jc\nucleo_wl55jc.dts:81 */
		};

		/* node '/clocks/pll' defined in zephyr\dts\arm\st\wl\stm32wl.dtsi:105 */
		pll: pll {
			#clock-cells = < 0x0 >;              /* in zephyr\dts\arm\st\wl\stm32wl.dtsi:106 */
			compatible = "st,stm32wb-pll-clock"; /* in zephyr\dts\arm\st\wl\stm32wl.dtsi:107 */
			div-m = < 0x1 >;                     /* in zephyr\boards\st\nucleo_wl55jc\nucleo_wl55jc.dts:99 */
			mul-n = < 0x6 >;                     /* in zephyr\boards\st\nucleo_wl55jc\nucleo_wl55jc.dts:100 */
			div-r = < 0x2 >;                     /* in zephyr\boards\st\nucleo_wl55jc\nucleo_wl55jc.dts:101 */
			div-q = < 0x2 >;                     /* in zephyr\boards\st\nucleo_wl55jc\nucleo_wl55jc.dts:102 */
			clocks = < &clk_hsi >;               /* in zephyr\boards\st\nucleo_wl55jc\nucleo_wl55jc.dts:103 */
			status = "okay";                     /* in zephyr\boards\st\nucleo_wl55jc\nucleo_wl55jc.dts:104 */
			phandle = < 0x2 >;                   /* in zephyr\boards\st\nucleo_wl55jc\nucleo_wl55jc.dts:108 */
		};
	};

	/* node '/mcos' defined in zephyr\dts\arm\st\wl\stm32wl.dtsi:112 */
	mcos {

		/* node '/mcos/mco1' defined in zephyr\dts\arm\st\wl\stm32wl.dtsi:113 */
		mco1: mco1 {
			compatible = "st,stm32-clock-mco"; /* in zephyr\dts\arm\st\wl\stm32wl.dtsi:114 */
			status = "disabled";               /* in zephyr\dts\arm\st\wl\stm32wl.dtsi:115 */
		};
	};

	/* node '/dietemp' defined in zephyr\dts\arm\st\wl\stm32wl.dtsi:549 */
	die_temp: dietemp {
		compatible = "st,stm32-temp-cal"; /* in zephyr\dts\arm\st\wl\stm32wl.dtsi:550 */
		ts-cal1-addr = < 0x1fff75a8 >;    /* in zephyr\dts\arm\st\wl\stm32wl.dtsi:551 */
		ts-cal2-addr = < 0x1fff75c8 >;    /* in zephyr\dts\arm\st\wl\stm32wl.dtsi:552 */
		ts-cal1-temp = < 0x1e >;          /* in zephyr\dts\arm\st\wl\stm32wl.dtsi:553 */
		ts-cal2-temp = < 0x82 >;          /* in zephyr\dts\arm\st\wl\stm32wl.dtsi:554 */
		ts-cal-vrefanalog = < 0xce4 >;    /* in zephyr\dts\arm\st\wl\stm32wl.dtsi:555 */
		io-channels = < &adc1 0xc >;      /* in zephyr\dts\arm\st\wl\stm32wl.dtsi:556 */
		status = "okay";                  /* in zephyr\boards\st\nucleo_wl55jc\nucleo_wl55jc.dts:163 */
	};

	/* node '/vref' defined in zephyr\dts\arm\st\wl\stm32wl.dtsi:560 */
	vref: vref {
		compatible = "st,stm32-vref";      /* in zephyr\dts\arm\st\wl\stm32wl.dtsi:561 */
		vrefint-cal-addr = < 0x1fff75aa >; /* in zephyr\dts\arm\st\wl\stm32wl.dtsi:562 */
		vrefint-cal-mv = < 0xce4 >;        /* in zephyr\dts\arm\st\wl\stm32wl.dtsi:563 */
		io-channels = < &adc1 0xd >;       /* in zephyr\dts\arm\st\wl\stm32wl.dtsi:564 */
		status = "okay";                   /* in zephyr\boards\st\nucleo_wl55jc\nucleo_wl55jc.dts:238 */
	};

	/* node '/vbat' defined in zephyr\dts\arm\st\wl\stm32wl.dtsi:568 */
	vbat: vbat {
		compatible = "st,stm32-vbat"; /* in zephyr\dts\arm\st\wl\stm32wl.dtsi:569 */
		ratio = < 0x3 >;              /* in zephyr\dts\arm\st\wl\stm32wl.dtsi:570 */
		io-channels = < &adc1 0xe >;  /* in zephyr\dts\arm\st\wl\stm32wl.dtsi:571 */
		status = "okay";              /* in zephyr\boards\st\nucleo_wl55jc\nucleo_wl55jc.dts:242 */
	};

	/* node '/smbus1' defined in zephyr\dts\arm\st\wl\stm32wl.dtsi:575 */
	smbus1: smbus1 {
		compatible = "st,stm32-smbus"; /* in zephyr\dts\arm\st\wl\stm32wl.dtsi:576 */
		#address-cells = < 0x1 >;      /* in zephyr\dts\arm\st\wl\stm32wl.dtsi:577 */
		#size-cells = < 0x0 >;         /* in zephyr\dts\arm\st\wl\stm32wl.dtsi:578 */
		i2c = < &i2c1 >;               /* in zephyr\dts\arm\st\wl\stm32wl.dtsi:579 */
		status = "disabled";           /* in zephyr\dts\arm\st\wl\stm32wl.dtsi:580 */
	};

	/* node '/smbus2' defined in zephyr\dts\arm\st\wl\stm32wl.dtsi:583 */
	smbus2: smbus2 {
		compatible = "st,stm32-smbus"; /* in zephyr\dts\arm\st\wl\stm32wl.dtsi:584 */
		#address-cells = < 0x1 >;      /* in zephyr\dts\arm\st\wl\stm32wl.dtsi:585 */
		#size-cells = < 0x0 >;         /* in zephyr\dts\arm\st\wl\stm32wl.dtsi:586 */
		i2c = < &i2c2 >;               /* in zephyr\dts\arm\st\wl\stm32wl.dtsi:587 */
		status = "disabled";           /* in zephyr\dts\arm\st\wl\stm32wl.dtsi:588 */
	};

	/* node '/smbus3' defined in zephyr\dts\arm\st\wl\stm32wl.dtsi:591 */
	smbus3: smbus3 {
		compatible = "st,stm32-smbus"; /* in zephyr\dts\arm\st\wl\stm32wl.dtsi:592 */
		#address-cells = < 0x1 >;      /* in zephyr\dts\arm\st\wl\stm32wl.dtsi:593 */
		#size-cells = < 0x0 >;         /* in zephyr\dts\arm\st\wl\stm32wl.dtsi:594 */
		i2c = < &i2c3 >;               /* in zephyr\dts\arm\st\wl\stm32wl.dtsi:595 */
		status = "disabled";           /* in zephyr\dts\arm\st\wl\stm32wl.dtsi:596 */
	};

	/* node '/connector' defined in zephyr\boards\st\nucleo_wl55jc\arduino_r3_connector.dtsi:10 */
	arduino_header: connector {
		compatible = "arduino-header-r3";          /* in zephyr\boards\st\nucleo_wl55jc\arduino_r3_connector.dtsi:11 */
		#gpio-cells = < 0x2 >;                     /* in zephyr\boards\st\nucleo_wl55jc\arduino_r3_connector.dtsi:12 */
		gpio-map-mask = < 0xffffffff 0xffffffc0 >; /* in zephyr\boards\st\nucleo_wl55jc\arduino_r3_connector.dtsi:13 */
		gpio-map-pass-thru = < 0x0 0x3f >;         /* in zephyr\boards\st\nucleo_wl55jc\arduino_r3_connector.dtsi:14 */
		gpio-map = < 0x0 0x0 &gpiob 0x1 0x0 >,
		           < 0x1 0x0 &gpiob 0x2 0x0 >,
		           < 0x2 0x0 &gpioa 0xa 0x0 >,
		           < 0x3 0x0 &gpiob 0x4 0x0 >,
		           < 0x4 0x0 &gpiob 0xe 0x0 >,
		           < 0x5 0x0 &gpiob 0xd 0x0 >,
		           < 0x6 0x0 &gpiob 0x7 0x0 >,
		           < 0x7 0x0 &gpiob 0x6 0x0 >,
		           < 0x8 0x0 &gpiob 0xc 0x0 >,
		           < 0x9 0x0 &gpiob 0x3 0x0 >,
		           < 0xa 0x0 &gpiob 0x5 0x0 >,
		           < 0xb 0x0 &gpiob 0x8 0x0 >,
		           < 0xc 0x0 &gpiob 0xa 0x0 >,
		           < 0xd 0x0 &gpioc 0x1 0x0 >,
		           < 0xe 0x0 &gpioc 0x2 0x0 >,
		           < 0xf 0x0 &gpioa 0x9 0x0 >,
		           < 0x10 0x0 &gpioa 0x4 0x0 >,
		           < 0x11 0x0 &gpioa 0x7 0x0 >,
		           < 0x12 0x0 &gpioa 0x6 0x0 >,
		           < 0x13 0x0 &gpioa 0x5 0x0 >,
		           < 0x14 0x0 &gpioa 0xb 0x0 >,
		           < 0x15 0x0 &gpioa 0xc 0x0 >;    /* in zephyr\boards\st\nucleo_wl55jc\arduino_r3_connector.dtsi:15 */
	};

	/* node '/st-morpho-header' defined in zephyr\boards\st\nucleo_wl55jc\st_morpho_connector.dtsi:10 */
	st_morpho_header: st-morpho-header {
		compatible = "st-morpho-header";        /* in zephyr\boards\st\nucleo_wl55jc\st_morpho_connector.dtsi:11 */
		#gpio-cells = < 0x2 >;                  /* in zephyr\boards\st\nucleo_wl55jc\st_morpho_connector.dtsi:12 */
		gpio-map-mask = < 0xff 0x0 >;           /* in zephyr\boards\st\nucleo_wl55jc\st_morpho_connector.dtsi:13 */
		gpio-map-pass-thru = < 0x0 0x7f >;      /* in zephyr\boards\st\nucleo_wl55jc\st_morpho_connector.dtsi:14 */
		gpio-map = < 0x6 0x0 &gpioh 0x3 0x0 >,
		           < 0xc 0x0 &gpioa 0xd 0x0 >,
		           < 0xe 0x0 &gpioa 0xe 0x0 >,
		           < 0x10 0x0 &gpioa 0xf 0x0 >,
		           < 0x16 0x0 &gpioc 0xd 0x0 >,
		           < 0x18 0x0 &gpioc 0xe 0x0 >,
		           < 0x1a 0x0 &gpioc 0xf 0x0 >,
		           < 0x1b 0x0 &gpiob 0x1 0x0 >,
		           < 0x1d 0x0 &gpiob 0x2 0x0 >,
		           < 0x1f 0x0 &gpioa 0xa 0x0 >,
		           < 0x21 0x0 &gpiob 0x4 0x0 >,
		           < 0x23 0x0 &gpiob 0xe 0x0 >,
		           < 0x25 0x0 &gpiob 0xd 0x0 >,
		           < 0x48 0x0 &gpioa 0x0 0x0 >,
		           < 0x49 0x0 &gpioc 0x4 0x0 >,
		           < 0x4a 0x0 &gpioa 0xc 0x0 >,
		           < 0x4b 0x0 &gpioc 0x5 0x0 >,
		           < 0x4c 0x0 &gpioa 0xb 0x0 >,
		           < 0x52 0x0 &gpioa 0x5 0x0 >,
		           < 0x53 0x0 &gpioc 0x6 0x0 >,
		           < 0x54 0x0 &gpioa 0x6 0x0 >,
		           < 0x55 0x0 &gpioc 0x0 0x0 >,
		           < 0x56 0x0 &gpioa 0x7 0x0 >,
		           < 0x57 0x0 &gpioa 0x8 0x0 >,
		           < 0x58 0x0 &gpioa 0x4 0x0 >,
		           < 0x5a 0x0 &gpioa 0x9 0x0 >,
		           < 0x5c 0x0 &gpioc 0x2 0x0 >,
		           < 0x5d 0x0 &gpiob 0x0 0x0 >,
		           < 0x5e 0x0 &gpioc 0x1 0x0 >,
		           < 0x60 0x0 &gpiob 0xa 0x0 >,
		           < 0x61 0x0 &gpiob 0x9 0x0 >,
		           < 0x62 0x0 &gpiob 0x8 0x0 >,
		           < 0x63 0x0 &gpiob 0xf 0x0 >,
		           < 0x64 0x0 &gpiob 0x5 0x0 >,
		           < 0x65 0x0 &gpiob 0xb 0x0 >,
		           < 0x66 0x0 &gpiob 0x3 0x0 >,
		           < 0x68 0x0 &gpiob 0xc 0x0 >,
		           < 0x6a 0x0 &gpiob 0x6 0x0 >,
		           < 0x6b 0x0 &gpioa 0x1 0x0 >,
		           < 0x6c 0x0 &gpiob 0x7 0x0 >,
		           < 0x6d 0x0 &gpioc 0x3 0x0 >; /* in zephyr\boards\st\nucleo_wl55jc\st_morpho_connector.dtsi:15 */
	};

	/* node '/leds' defined in zephyr\boards\st\nucleo_wl55jc\nucleo_wl55jc.dts:26 */
	leds: leds {
		compatible = "gpio-leds"; /* in zephyr\boards\st\nucleo_wl55jc\nucleo_wl55jc.dts:27 */

		/* node '/leds/led_0' defined in zephyr\boards\st\nucleo_wl55jc\nucleo_wl55jc.dts:29 */
		blue_led_1: led_0 {
			gpios = < &gpiob 0xf 0x0 >; /* in zephyr\boards\st\nucleo_wl55jc\nucleo_wl55jc.dts:30 */
			label = "User LED1";        /* in zephyr\boards\st\nucleo_wl55jc\nucleo_wl55jc.dts:31 */
		};

		/* node '/leds/led_1' defined in zephyr\boards\st\nucleo_wl55jc\nucleo_wl55jc.dts:34 */
		green_led_2: led_1 {
			gpios = < &gpiob 0x9 0x0 >; /* in zephyr\boards\st\nucleo_wl55jc\nucleo_wl55jc.dts:35 */
			label = "User LED2";        /* in zephyr\boards\st\nucleo_wl55jc\nucleo_wl55jc.dts:36 */
		};

		/* node '/leds/led_2' defined in zephyr\boards\st\nucleo_wl55jc\nucleo_wl55jc.dts:39 */
		red_led_3: led_2 {
			gpios = < &gpiob 0xb 0x0 >; /* in zephyr\boards\st\nucleo_wl55jc\nucleo_wl55jc.dts:40 */
			label = "User LED3";        /* in zephyr\boards\st\nucleo_wl55jc\nucleo_wl55jc.dts:41 */
		};
	};

	/* node '/gpio_keys' defined in zephyr\boards\st\nucleo_wl55jc\nucleo_wl55jc.dts:45 */
	gpio_keys {
		compatible = "gpio-keys"; /* in zephyr\boards\st\nucleo_wl55jc\nucleo_wl55jc.dts:46 */

		/* node '/gpio_keys/button_0' defined in zephyr\boards\st\nucleo_wl55jc\nucleo_wl55jc.dts:48 */
		user_button_1: button_0 {
			label = "SW1";               /* in zephyr\boards\st\nucleo_wl55jc\nucleo_wl55jc.dts:49 */
			gpios = < &gpioa 0x0 0x11 >; /* in zephyr\boards\st\nucleo_wl55jc\nucleo_wl55jc.dts:50 */
			zephyr,code = < 0xb >;       /* in zephyr\boards\st\nucleo_wl55jc\nucleo_wl55jc.dts:51 */
		};

		/* node '/gpio_keys/button_1' defined in zephyr\boards\st\nucleo_wl55jc\nucleo_wl55jc.dts:54 */
		user_button_2: button_1 {
			label = "SW2";               /* in zephyr\boards\st\nucleo_wl55jc\nucleo_wl55jc.dts:55 */
			gpios = < &gpioa 0x1 0x11 >; /* in zephyr\boards\st\nucleo_wl55jc\nucleo_wl55jc.dts:56 */
			zephyr,code = < 0x2 >;       /* in zephyr\boards\st\nucleo_wl55jc\nucleo_wl55jc.dts:57 */
		};

		/* node '/gpio_keys/button_2' defined in zephyr\boards\st\nucleo_wl55jc\nucleo_wl55jc.dts:60 */
		user_button_3: button_2 {
			label = "SW3";               /* in zephyr\boards\st\nucleo_wl55jc\nucleo_wl55jc.dts:61 */
			gpios = < &gpioc 0x6 0x11 >; /* in zephyr\boards\st\nucleo_wl55jc\nucleo_wl55jc.dts:62 */
			zephyr,code = < 0x3 >;       /* in zephyr\boards\st\nucleo_wl55jc\nucleo_wl55jc.dts:63 */
		};
	};
};
